# ELM register map
Vendor: Texas Instruments
Peripheral module from a debugger description file (folder 66AK2G0x_66AK2G1x).
Registers are 32-bit, access per field, reset values left out (the file's numbers can be read two ways) unless marked. A register's access mark holds for its fields unless they carry their own. Offsets are as the file gives them; lines under a group give offsets from that group; [hi:lo] are bit positions; {n}, {i} and the like mark numbered series; 'fields as' and 'values as' point back to an identical list; <NAME> marks a mode.

## ELM
0x00 ELM_REVISION ro
  [31:0] REVISION — TI internal data. Identifies revision of peripheral.
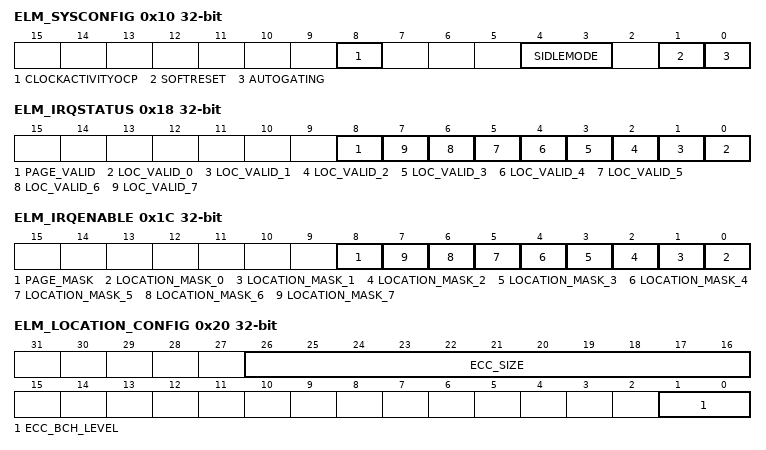
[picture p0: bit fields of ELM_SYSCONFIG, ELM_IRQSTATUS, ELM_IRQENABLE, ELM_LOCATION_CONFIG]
0x10 ELM_SYSCONFIG
  [8] CLOCKACTIVITYOCP rw — ELM_CLK activity when module is in IDLE mode 0h (R/W) = ELM_CLK can be switched off. 1h (R/W) = ELM_CLK is maintained.
  [4:3] SIDLEMODE rw — Slave interface power management (IDLE req/ack control) 0h (R/W) = Force-idle. IDLE request is acknowledged unconditionally and immediately 1h (R/W) = No-idle. IDLE request is never acknowledged. 2h (R/W) = Smart-idle. The acknowledgment to an IDLE request is given based on the internal activity. 3h (R/W) = Reserved do not use
  [1] SOFTRESET rw — Module software reset 0h (R/W) = Normal mode 1h (R/W) = Start soft reset sequence.
  [0] AUTOGATING rw — Internal ELM_CLK gating strategy 0h (R/W) = ELM_CLK is free-running. 1h (R/W) = Automatic internal ELM_CLK gating strategy is applied based on the Interconnect interface activity.
0x14 ELM_SYSSTATUS ro
  [0] RESETDONE — Internal reset monitoring 0h (R) = Reset is ongoing. 1h (R) = Reset is done (completed).
0x18 ELM_IRQSTATUS
  [8] PAGE_VALID rw — Error-location status for a full page, based on the mask definition
  [n] LOC_VALID_{n} rw (n=0..7) — Error-location status for syndrome polynomial {n}
0x1C ELM_IRQENABLE
  [8] PAGE_MASK rw — Page interrupt mask bit
  [n] LOCATION_MASK_{n} rw (n=0..7) — Error-location interrupt mask bit for syndrome polynomial {n}
0x20 ELM_LOCATION_CONFIG
  [26:16] ECC_SIZE rw — Maximum size of the buffers for which the error-location engine is used, in number of nibbles (4-bit entities)
  [1:0] ECC_BCH_LEVEL rw — Error correction level
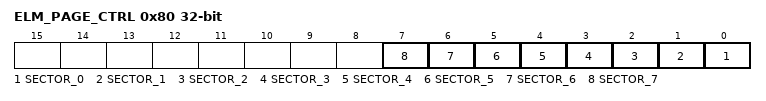
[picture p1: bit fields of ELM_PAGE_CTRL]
0x80 ELM_PAGE_CTRL
  [n] SECTOR_{n} rw (n=0..7) — Set to 1 if syndrome polynomial {n} is part of the page in page mode. Must be 0 in continuous mode.
